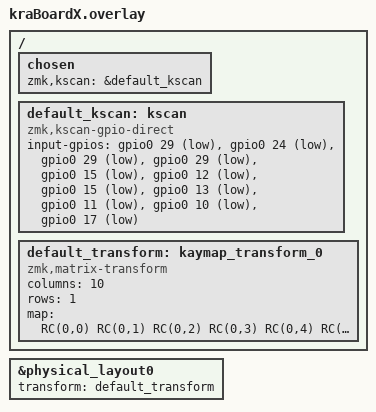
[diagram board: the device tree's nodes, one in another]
#include <dt-bindings/zmk/matrix_transform.h>
#include "kraBoardX-layouts.dtsi"


&physical_layout0 {
    transform = <&default_transform>;
};

/ {
    chosen {
        zmk,kscan = &default_kscan;
    };
    default_kscan: kscan {
        compatible = "zmk,kscan-gpio-direct";
        input-gpios
            = <&gpio0 29 (GPIO_ACTIVE_LOW | GPIO_PULL_UP)>
            , <&gpio0 24 (GPIO_ACTIVE_LOW | GPIO_PULL_UP)>
            , <&gpio0 29 (GPIO_ACTIVE_LOW | GPIO_PULL_UP)>
            , <&gpio0 29 (GPIO_ACTIVE_LOW | GPIO_PULL_UP)>
            , <&gpio0 15 (GPIO_ACTIVE_LOW | GPIO_PULL_UP)>
            , <&gpio0 12 (GPIO_ACTIVE_LOW | GPIO_PULL_UP)>
            , <&gpio0 15 (GPIO_ACTIVE_LOW | GPIO_PULL_UP)>
            , <&gpio0 13 (GPIO_ACTIVE_LOW | GPIO_PULL_UP)>
            , <&gpio0 11 (GPIO_ACTIVE_LOW | GPIO_PULL_UP)>
            , <&gpio0 10 (GPIO_ACTIVE_LOW | GPIO_PULL_UP)>
            , <&gpio0 17 (GPIO_ACTIVE_LOW | GPIO_PULL_UP)>
            ;
    };
    default_transform: kaymap_transform_0 {
        compatible = "zmk,matrix-transform";
        columns = <10>;
        rows = <1>;
        map = <
            RC(0,0) RC(0,1) RC(0,2) RC(0,3) RC(0,4) RC(0,5) RC(0,6) RC(0,7) RC(0,8) RC(0,9) RC(0,10)
        >;
    };
};


